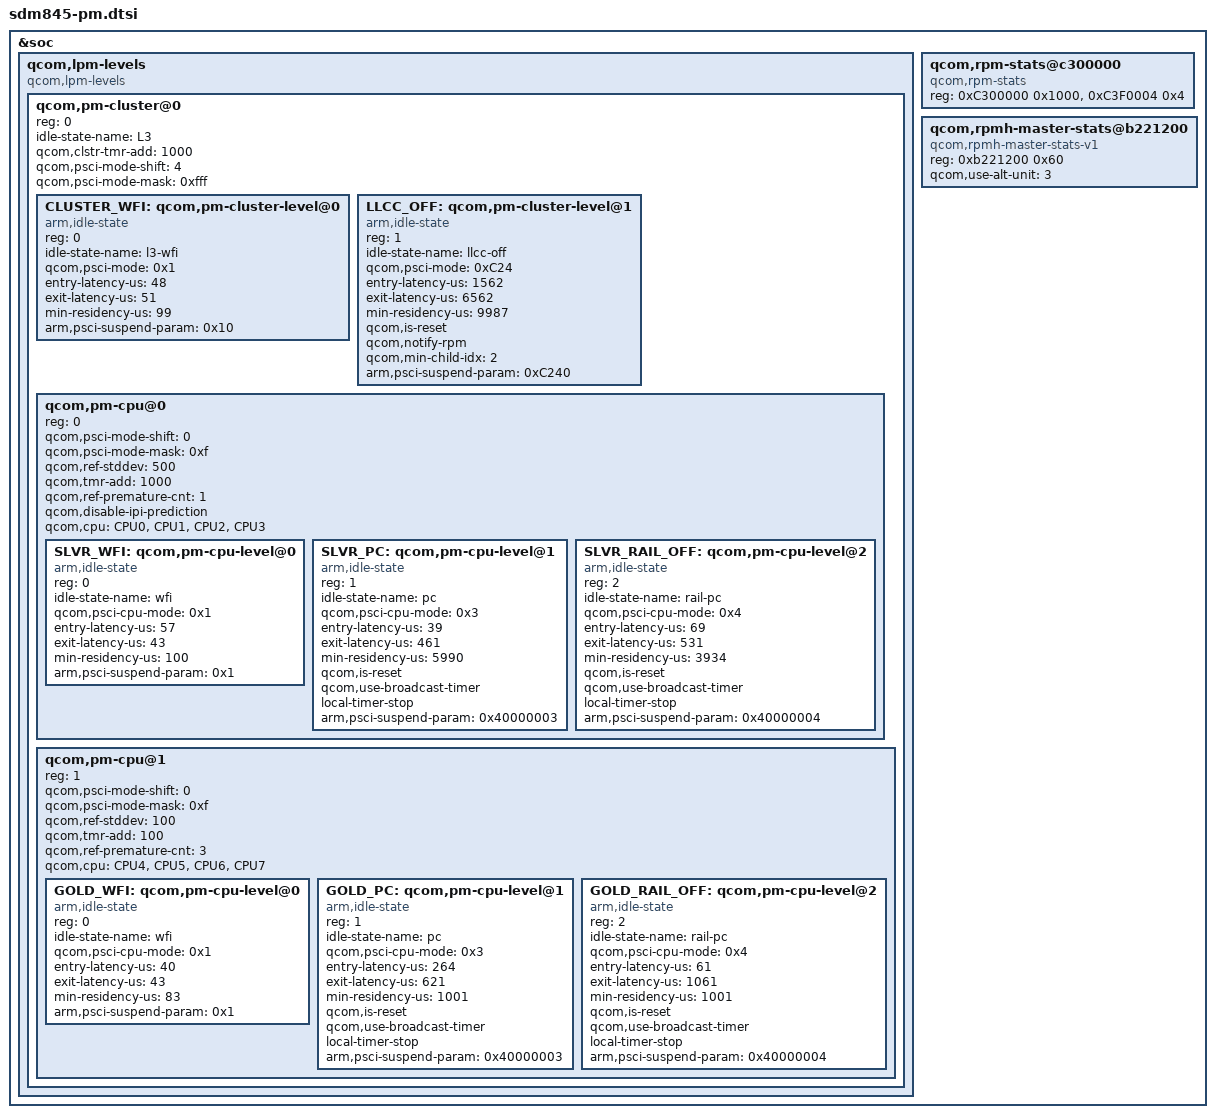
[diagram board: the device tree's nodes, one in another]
// SPDX-License-Identifier: GPL-2.0-only
/*
 * Copyright (c) 2016-2018, The Linux Foundation. All rights reserved.
 * Copyright (c) 2021, 2025, Pavel Dubrova <pashadubrova@gmail.com>
 */

&soc {
	qcom,lpm-levels {
		compatible = "qcom,lpm-levels";
		#address-cells = <1>;
		#size-cells = <0>;

		qcom,pm-cluster@0 {
			reg = <0>;
			#address-cells = <1>;
			#size-cells = <0>;
			idle-state-name = "L3";
			qcom,clstr-tmr-add = <1000>;
			qcom,psci-mode-shift = <4>;
			qcom,psci-mode-mask = <0xfff>;

			CLUSTER_WFI: qcom,pm-cluster-level@0 { /* D1 */
				reg = <0>;
				compatible = "arm,idle-state";
				idle-state-name = "l3-wfi";
				qcom,psci-mode = <0x1>;
				entry-latency-us = <48>;
				exit-latency-us = <51>;
				min-residency-us = <99>;
				arm,psci-suspend-param = <0x10>;
			};

			LLCC_OFF: qcom,pm-cluster-level@1 { /* AOSS sleep */
				reg = <1>;
				compatible = "arm,idle-state";
				idle-state-name = "llcc-off";
				qcom,psci-mode = <0xC24>;
				entry-latency-us = <1562>;
				exit-latency-us = <6562>;
				min-residency-us = <9987>;
				qcom,is-reset;
				qcom,notify-rpm;
				qcom,min-child-idx = <2>;
				arm,psci-suspend-param = <0xC240>;
			};

			qcom,pm-cpu@0 {
				reg = <0>;
				#address-cells = <1>;
				#size-cells = <0>;
				qcom,psci-mode-shift = <0>;
				qcom,psci-mode-mask = <0xf>;
				qcom,ref-stddev = <500>;
				qcom,tmr-add = <1000>;
				qcom,ref-premature-cnt = <1>;
				qcom,disable-ipi-prediction;
				qcom,cpu = <&CPU0 &CPU1 &CPU2 &CPU3>;

				SLVR_WFI: qcom,pm-cpu-level@0 { /* C1 */
					reg = <0>;
					compatible = "arm,idle-state";
					idle-state-name = "wfi";
					qcom,psci-cpu-mode = <0x1>;
					entry-latency-us = <57>;
					exit-latency-us = <43>;
					min-residency-us = <100>;
					arm,psci-suspend-param = <0x1>;
				};

				SLVR_PC: qcom,pm-cpu-level@1 {  /* C3 */
					reg = <1>;
					compatible = "arm,idle-state";
					idle-state-name = "pc";
					qcom,psci-cpu-mode = <0x3>;
					entry-latency-us = <39>;
					exit-latency-us = <461>;
					min-residency-us = <5990>;
					qcom,is-reset;
					qcom,use-broadcast-timer;
					local-timer-stop;
					arm,psci-suspend-param = <0x40000003>;
				};

				SLVR_RAIL_OFF: qcom,pm-cpu-level@2 {  /* C4 */
					reg = <2>;
					compatible = "arm,idle-state";
					idle-state-name = "rail-pc";
					qcom,psci-cpu-mode = <0x4>;
					entry-latency-us = <69>;
					exit-latency-us = <531>;
					min-residency-us = <3934>;
					qcom,is-reset;
					qcom,use-broadcast-timer;
					local-timer-stop;
					arm,psci-suspend-param = <0x40000004>;
				};
			};

			qcom,pm-cpu@1 {
				reg = <1>;
				#address-cells = <1>;
				#size-cells = <0>;
				qcom,psci-mode-shift = <0>;
				qcom,psci-mode-mask = <0xf>;
				qcom,ref-stddev = <100>;
				qcom,tmr-add = <100>;
				qcom,ref-premature-cnt = <3>;
				qcom,cpu = <&CPU4 &CPU5 &CPU6 &CPU7>;

				GOLD_WFI: qcom,pm-cpu-level@0 { /* C1 */
					reg = <0>;
					compatible = "arm,idle-state";
					idle-state-name = "wfi";
					qcom,psci-cpu-mode = <0x1>;
					entry-latency-us = <40>;
					exit-latency-us = <43>;
					min-residency-us = <83>;
					arm,psci-suspend-param = <0x1>;
				};

				GOLD_PC: qcom,pm-cpu-level@1 {  /* C3 */
					reg = <1>;
					compatible = "arm,idle-state";
					idle-state-name = "pc";
					qcom,psci-cpu-mode = <0x3>;
					entry-latency-us = <264>;
					exit-latency-us = <621>;
					min-residency-us = <1001>;
					qcom,is-reset;
					qcom,use-broadcast-timer;
					local-timer-stop;
					arm,psci-suspend-param = <0x40000003>;
				};

				GOLD_RAIL_OFF: qcom,pm-cpu-level@2 {  /* C4 */
					reg = <2>;
					compatible = "arm,idle-state";
					idle-state-name = "rail-pc";
					qcom,psci-cpu-mode = <0x4>;
					entry-latency-us = <61>;
					exit-latency-us = <1061>;
					min-residency-us = <1001>;
					qcom,is-reset;
					qcom,use-broadcast-timer;
					local-timer-stop;
					arm,psci-suspend-param = <0x40000004>;
				};
			};
		};
	};

	qcom,rpm-stats@c300000 {
		compatible = "qcom,rpm-stats";
		reg = <0xC300000 0x1000>, <0xC3F0004 0x4>;
		reg-names = "phys_addr_base", "offset_addr";
	};

	qcom,rpmh-master-stats@b221200 {
		compatible = "qcom,rpmh-master-stats-v1";
		reg = <0xb221200 0x60>;
		qcom,use-alt-unit = <3>;
	};
};
